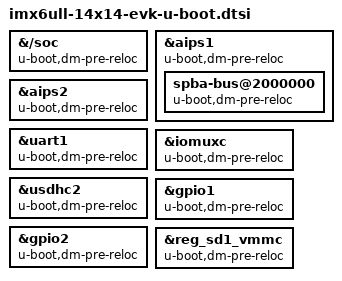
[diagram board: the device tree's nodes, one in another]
// SPDX-License-Identifier: GPL-2.0+
/*
 * Copyright 2020 Foundries.io
 */

&{/soc} {
	u-boot,dm-pre-reloc;
	u-boot,dm-spl;
};

&aips1 {
	u-boot,dm-pre-reloc;
	u-boot,dm-spl;

	spba-bus@2000000 {
		u-boot,dm-pre-reloc;
		u-boot,dm-spl;
	};
};

&aips2 {
	u-boot,dm-pre-reloc;
	u-boot,dm-spl;
};

&uart1 {
	u-boot,dm-pre-reloc;
	u-boot,dm-spl;
};

&iomuxc {
	u-boot,dm-pre-reloc;
	u-boot,dm-spl;
};

/* only enable the active boot device */
&usdhc2 {
        u-boot,dm-pre-reloc;
        u-boot,dm-spl;
};

&gpio1 {
        u-boot,dm-pre-reloc;
        u-boot,dm-spl;
};

&gpio2 {
        u-boot,dm-pre-reloc;
        u-boot,dm-spl;
};

&reg_sd1_vmmc {
        u-boot,dm-pre-reloc;
        u-boot,dm-spl;
};
